AUTOSAR XML (schema 4-2-1)
package /ComponentTypes
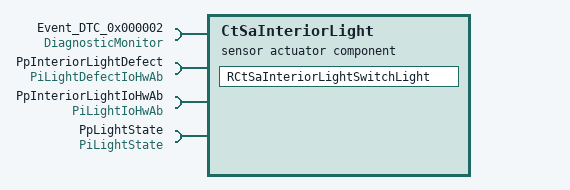
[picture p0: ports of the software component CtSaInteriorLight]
  sensor actuator sw component type CtSaInteriorLight
    4 x require port:
      Event_DTC_0x000002: required-interface=DiagnosticMonitor
      PpInteriorLightDefect: required-interface=PiLightDefectIoHwAb
      PpInteriorLightIoHwAb: required-interface=PiLightIoHwAb
      PpLightState: nonqueued-receiver-com-spec{data-element=DeLightState, filter=data-filter-type=ALWAYS, init-value=constant-reference=CLightOff}, required-interface=PiLightState
    behavior CtSaInteriorLight_InternalBehavior: data-type-mapping=DemoTypeMapping, supports-multiple-instantiation=true
      data received event DRT_RCtSaInteriorLightSwitchLight_PpLightState_Element: start-on-event=RCtSaInteriorLightSwitchLight, data=PpLightState.DeLightState
      runnable RCtSaInteriorLightSwitchLight
        data-receive-point-by-arguments:
          access REC_PpLightState_Element: accessed-variable=PpLightState.DeLightState
        sync call SC_Event_DTC_0x000002_SetEventStatus: operation=Event_DTC_0x000002.SetEventStatus, timeout=0
        sync call SC_PpInteriorLightDefect_ReadChannel: operation=PpInteriorLightDefect.ReadChannel, timeout=0
        sync call SC_PpInteriorLightIoHwAb_WriteChannel: operation=PpInteriorLightIoHwAb.WriteChannel, timeout=0
  swc implementation CtSaInteriorLight_Implementation: behavior=CtSaInteriorLight_InternalBehavior
    code-descriptors:
      code Default: artifact-descriptors=autosar-engineering-object={short-label=Default, category=SWSRC}
